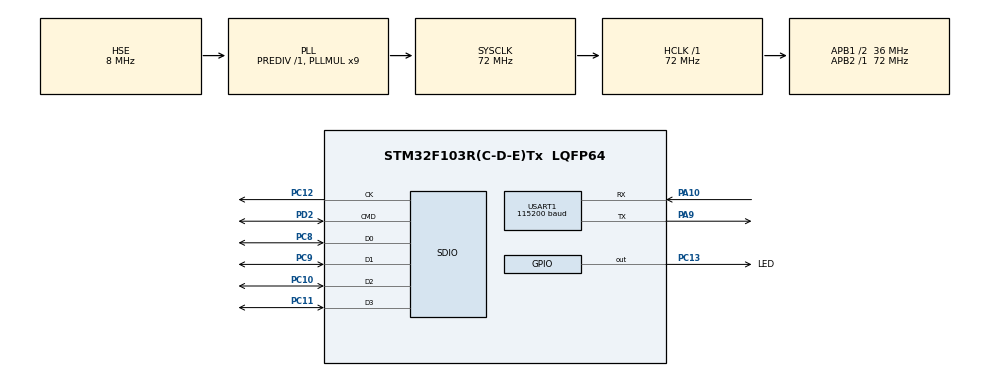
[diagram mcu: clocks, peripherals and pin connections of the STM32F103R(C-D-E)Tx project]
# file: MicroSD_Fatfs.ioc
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FATFS.SD_BSP_CODE=0
FATFS._CODE_PAGE=850
FATFS._FS_LOCK=2
FATFS._FS_MINIMIZE=0
FATFS._FS_NOFSINFO=0
FATFS._FS_NORTC=0
FATFS._FS_READONLY=0
FATFS._FS_REENTRANT=0
FATFS._FS_RPATH=0
FATFS._FS_TIMEOUT=1000
FATFS._FS_TINY=0
FATFS._HSD=hsd
FATFS._LFN_UNICODE=0
FATFS._MAX_LFN=255
FATFS._MAX_SS=512
FATFS._MIN_SS=512
FATFS._MULTI_PARTITION=0
FATFS._STRF_ENCODE=3
FATFS._USE_FASTSEEK=1
FATFS._USE_FIND=0
FATFS._USE_FORWARD=0
FATFS._USE_LABEL=0
FATFS._USE_LFN=0
FATFS._USE_MKFS=1
FATFS._USE_STRFUNC=2
FATFS._USE_TRIM=0
FATFS._VOLUMES=1
FATFS._WORD_ACCESS=0
Mcu.Family=STM32F1
Mcu.Name=STM32F103R(C-D-E)Tx
Mcu.Package=LQFP64
NVIC.PriorityGroup=NVIC_PRIORITYGROUP_4
NVIC.SDIO_IRQn=true\:3\:0\:true\:false\:true\:true\:true\:true
PA10.Mode=Asynchronous
PA10.Signal=USART1_RX
PA13.Mode=Serial_Wire
PA13.Signal=SYS_JTMS-SWDIO
PA14.Mode=Serial_Wire
PA14.Signal=SYS_JTCK-SWCLK
PA9.Mode=Asynchronous
PA9.Signal=USART1_TX
PC10.Mode=SD_4_bits_Wide_bus
PC10.Signal=SDIO_D2
PC11.Mode=SD_4_bits_Wide_bus
PC11.Signal=SDIO_D3
PC12.GPIO_Speed_High_Default=GPIO_SPEED_FREQ_HIGH
PC12.Mode=SD_4_bits_Wide_bus
PC12.Signal=SDIO_CK
PC13-TAMPER-RTC.GPIO_Label=LED
PC13-TAMPER-RTC.PinState=GPIO_PIN_SET
PC13-TAMPER-RTC.Signal=GPIO_Output
PC8.GPIO_Speed_High_Default=GPIO_SPEED_FREQ_HIGH
PC8.Mode=SD_4_bits_Wide_bus
PC8.Signal=SDIO_D0
PC9.Mode=SD_4_bits_Wide_bus
PC9.Signal=SDIO_D1
PD0-OSC_IN.Mode=HSE-External-Oscillator
PD0-OSC_IN.Signal=RCC_OSC_IN
PD1-OSC_OUT.Mode=HSE-External-Oscillator
PD1-OSC_OUT.Signal=RCC_OSC_OUT
PD2.GPIO_Speed_High_Default=GPIO_SPEED_FREQ_HIGH
PD2.Mode=SD_4_bits_Wide_bus
PD2.Signal=SDIO_CMD
ProjectManager.HeapSize=0x800
ProjectManager.StackSize=0x2000
ProjectManager.TargetToolchain=MDK-ARM V5.32
RCC.AHBFreq_Value=72000000
RCC.APB1CLKDivider=RCC_HCLK_DIV2
RCC.APB1Freq_Value=36000000
RCC.APB1TimFreq_Value=72000000
RCC.APB2Freq_Value=72000000
RCC.APB2TimFreq_Value=72000000
RCC.FLatency=FLASH_LATENCY_2
RCC.HCLKFreq_Value=72000000
RCC.PLLMUL=RCC_PLL_MUL9
RCC.PLLSourceVirtual=RCC_PLLSOURCE_HSE
RCC.SYSCLKFreq_VALUE=72000000
RCC.SYSCLKSource=RCC_SYSCLKSOURCE_PLLCLK
RCC.USBFreq_Value=72000000
SDIO.ClockBypass=SDIO_CLOCK_BYPASS_DISABLE
SDIO.ClockDiv=2
SDIO.ClockEdge=SDIO_CLOCK_EDGE_RISING
SDIO.ClockPowerSave=SDIO_CLOCK_POWER_SAVE_DISABLE
SDIO.HardwareFlowControl=SDIO_HARDWARE_FLOW_CONTROL_DISABLE
USART1.BaudRate=115200
USART1.Mode=MODE_TX_RX
USART1.Parity=PARITY_NONE
USART1.StopBits=STOPBITS_1
USART1.VirtualMode=VM_ASYNC
USART1.WordLength=WORDLENGTH_8B
VP_FATFS_VS_SDIO.Mode=SDIO
board=custom

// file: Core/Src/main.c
/* USER CODE BEGIN Header */
/**
  ******************************************************************************
  * @file           : main.c
  * @brief          : Main program body
  ******************************************************************************
  * @attention
  *
  * Copyright (c) 2023 STMicroelectronics.
  * All rights reserved.
  *
  * This software is licensed under terms that can be found in the LICENSE file
  * in the root directory of this software component.
  * If no LICENSE file comes with this software, it is provided AS-IS.
  *
  ******************************************************************************
  */
/* USER CODE END Header */
#include "main.h"
#include "fatfs.h"
#include "sdio.h"
#include "usart.h"
#include "gpio.h"

/* USER CODE BEGIN Includes */
#include <stdio.h>
/* USER CODE END Includes */

void SystemClock_Config(void);

/* USER CODE BEGIN 0 */
void app_fatfs(void);
int fputc(int ch, FILE *f)
{
    HAL_UART_Transmit(&huart1, (uint8_t *)&ch, 1, 1000);

    return ch;
}
/* USER CODE END 0 */

int main(void)
{

  /* MCU Configuration--------------------------------------------------------*/

  /* Reset of all peripherals, Initializes the Flash interface and the Systick. */
  HAL_Init();

  /* Configure the system clock */
  SystemClock_Config();

  /* Initialize all configured peripherals */
  MX_GPIO_Init();
  MX_SDIO_SD_Init();
  MX_FATFS_Init();
  MX_USART1_UART_Init();
  /* USER CODE BEGIN 2 */
  HAL_Delay(100);
  printf("\r\n");

	app_fatfs();
  /* USER CODE END 2 */

  /* Infinite loop */
  while (1)
  {

  }
}

void SystemClock_Config(void)
{
  RCC_OscInitTypeDef RCC_OscInitStruct = {0};
  RCC_ClkInitTypeDef RCC_ClkInitStruct = {0};

  /** Initializes the RCC Oscillators according to the specified parameters
  * in the RCC_OscInitTypeDef structure.
  */
  RCC_OscInitStruct.OscillatorType = RCC_OSCILLATORTYPE_HSE;
  RCC_OscInitStruct.HSEState = RCC_HSE_ON;
  RCC_OscInitStruct.HSEPredivValue = RCC_HSE_PREDIV_DIV1;
  RCC_OscInitStruct.HSIState = RCC_HSI_ON;
  RCC_OscInitStruct.PLL.PLLState = RCC_PLL_ON;
  RCC_OscInitStruct.PLL.PLLSource = RCC_PLLSOURCE_HSE;
  RCC_OscInitStruct.PLL.PLLMUL = RCC_PLL_MUL9;
  if (HAL_RCC_OscConfig(&RCC_OscInitStruct) != HAL_OK)
  {
    Error_Handler();
  }

  /** Initializes the CPU, AHB and APB buses clocks
  */
  RCC_ClkInitStruct.ClockType = RCC_CLOCKTYPE_HCLK|RCC_CLOCKTYPE_SYSCLK
                              |RCC_CLOCKTYPE_PCLK1|RCC_CLOCKTYPE_PCLK2;
  RCC_ClkInitStruct.SYSCLKSource = RCC_SYSCLKSOURCE_PLLCLK;
  RCC_ClkInitStruct.AHBCLKDivider = RCC_SYSCLK_DIV1;
  RCC_ClkInitStruct.APB1CLKDivider = RCC_HCLK_DIV2;
  RCC_ClkInitStruct.APB2CLKDivider = RCC_HCLK_DIV1;

  if (HAL_RCC_ClockConfig(&RCC_ClkInitStruct, FLASH_LATENCY_2) != HAL_OK)
  {
    Error_Handler();
  }
}

void Error_Handler(void)
{
  /* USER CODE BEGIN Error_Handler_Debug */
  /* User can add his own implementation to report the HAL error return state */
  while (1)
  {
			HAL_GPIO_TogglePin(LED_GPIO_Port, LED_Pin);
			HAL_Delay(300);
  }
  /* USER CODE END Error_Handler_Debug */
}
